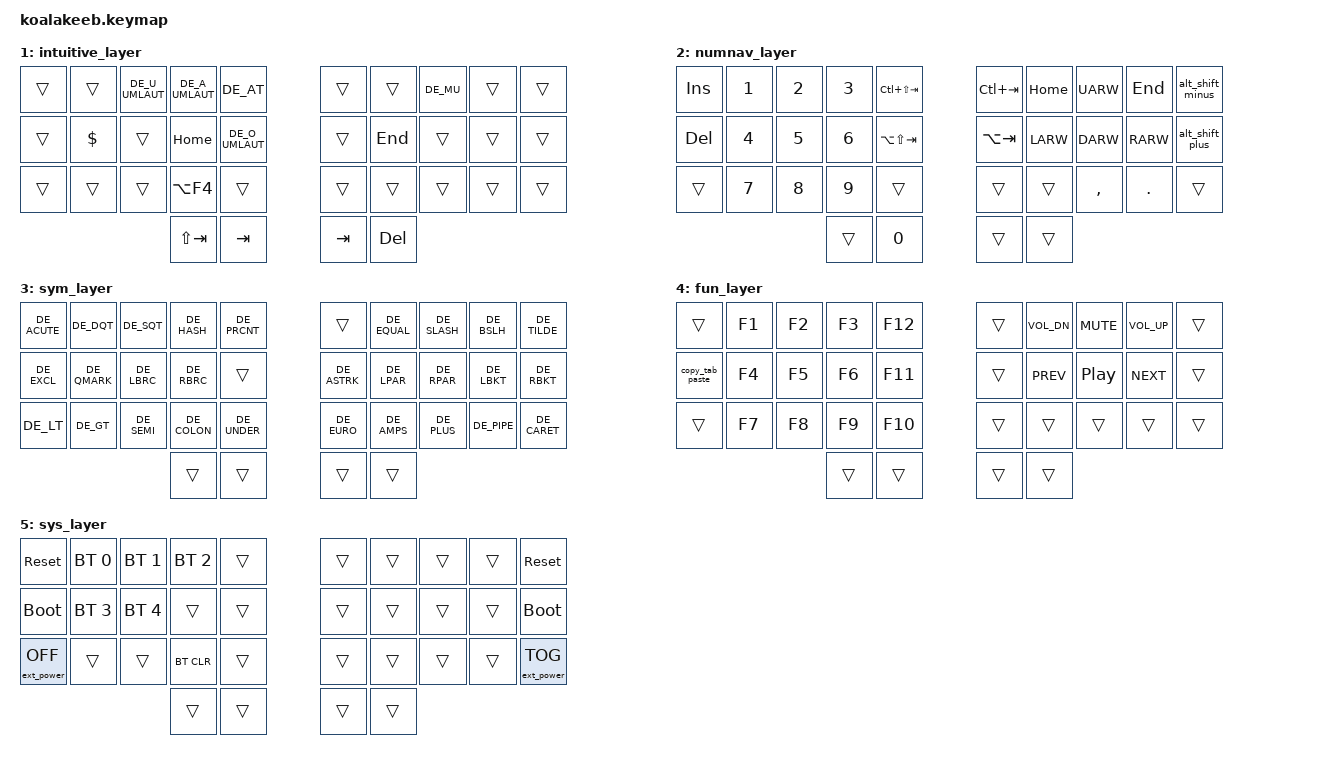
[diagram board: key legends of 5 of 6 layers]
// Copyright (c) 2022 The ZMK Contributors
// SPDX-License-Identifier: MIT

#include <behaviors.dtsi>
#include <dt-bindings/zmk/keys.h>
#include <dt-bindings/zmk/bt.h>
#include <dt-bindings/zmk/ext_power.h>
#include "keys_de.h"

// Home row mods macro
#define HRML(k1,k2,k3) &ht LALT k1  &ht LCTRL k2  &ht LGUI k3
#define HRMR(k1,k2,k3) &ht RGUI k1  &ht RCTRL k2  &ht RALT k3

/ {
    behaviors {
        ht: hold_tap {
            label = "hold_tap";
            compatible = "zmk,behavior-hold-tap";
            #binding-cells = <2>;
            flavor = "tap-preferred";
            tapping-term-ms = <220>;
            quick-tap-ms = <150>;
            global-quick-tap;
            bindings = <&kp>, <&kp>;
        };
    };

     combos {
         compatible = "zmk,combos";
         combo_esc {
            timeout-ms = <50>;
            key-positions = <0 10>;
            bindings = <&kp ESC>;
            layers = <0>;
         };
         combo_esc2 {
            timeout-ms = <50>;
            key-positions = <0 9>;
            bindings = <&kp ESC>;
            layers = <0>;
         };
         combo_capsword {
            timeout-ms = <50>;
            key-positions = <20 29>;
            bindings = <&caps_word>;
            layers = <0>;
         };
         combo_layer_sys {
             timeout-ms = <50>;
             key-positions = <30 31 32 33>;
             bindings = <&mo 5>;
         };
         combo_layer_fun {
             timeout-ms = <50>;
             key-positions = <30 31>;
             bindings = <&mo 4>;
         };
         combo_layer_fun2 {
             timeout-ms = <50>;
             key-positions = <30 33>;
             bindings = <&mo 4>;
         };
     };

     macros {
        copy_tab_paste: copy_tab_paste {
            compatible = "zmk,behavior-macro";
            #binding-cells = <0>;
            bindings
                = <&macro_press &kp LCTRL>
                , <&macro_tap &kp C &kp T &kp V>
                , <&macro_release &kp LCTRL>
                , <&macro_tap &kp ENTER>;
        };
        alt_shift_plus: alt_shift_plus {
            compatible = "zmk,behavior-macro";
            #binding-cells = <0>;
            bindings
                = <&macro_press &kp LALT>
                , <&macro_press &kp LSHFT>
                , <&macro_tap &kp DE_PLUS>
                , <&macro_release &kp LSHFT>
                , <&macro_release &kp LALT>;
        };
        alt_shift_minus: alt_shift_minus {
            compatible = "zmk,behavior-macro";
            #binding-cells = <0>;
            bindings
                = <&macro_press &kp LALT>
                , <&macro_press &kp LSHFT>
                , <&macro_tap &kp DE_MINUS>
                , <&macro_release &kp LSHFT>
                , <&macro_release &kp LALT>;
        };
     };

    keymap {
        compatible = "zmk,keymap";
        noted_layer {
            bindings = <
        //╭──────────┬──────────┬──────────┬──────────┬──────────╮   ╭──────────┬──────────┬──────────┬──────────┬──────────╮
        //│  Z       │  Y       │  U       │  A       │  Q       │   │  P       │  B       │  M       │  L       │  F       │
            &kp DE_Z   &kp DE_Y   &kp U      &kp A      &kp Q          &kp P      &kp B      &kp M      &kp L      &kp F
        //├──────────┼──────────┼──────────┼──────────┼──────────┤   ├──────────┼──────────┼──────────┼──────────┼──────────┤
        //│  C       │  S       │  I       │  E       │  O       │   │  D       │  T       │  N       │  R       │  H       │
            &lt 1 C    HRML(S,         I,         E)     &kp O          &kp D      HRMR(T,        N,         R)    &lt 1 H
        //├──────────┼──────────┼──────────┼──────────┼──────────┤   ├──────────┼──────────┼──────────┼──────────┼──────────┤
        //│  V       │  X       │  ,       │  .       │  -       │   │  W       │  G       │ J        │ ß        │   K      │
            &kp V      &kp X     &kp DE_COMMA &kp DE_DOT &kp DE_MINUS   &kp W      &kp G      &kp J     &kp DE_SZ    &kp K
        //╰──────────┴──────────┴──────────┼──────────┼──────────┤   ├──────────┼──────────┼──────────┴──────────┴──────────╯
                                            &lt 3 ENTER &kp LSHIFT    &kp SPACE   &lt 2 BSPC
        //                                 ╰──────────┴──────────╯   ╰──────────┴──────────╯
            >;
        };

        intuitive_layer {
            bindings = <
        //╭──────────┬──────────┬──────────┬──────────┬──────────╮   ╭──────────┬──────────┬──────────┬──────────┬──────────╮
        //│          │          │  Ü       │  Ä       │  @       │   │          │          │  µ       │          │          │
            &trans     &trans &kp DE_U_UMLAUT &kp DE_A_UMLAUT &kp DE_AT &trans     &trans     &kp DE_MU  &trans    &trans
        //├──────────┼──────────┼──────────┼──────────┼──────────┤   ├──────────┼──────────┼──────────┼──────────┼──────────┤
        //│          │          │          │ POS 1    │  Ö       │   │          │ END      │          │          │          │
            &trans     &kp DOLLAR &trans     &kp HOME  &kp DE_O_UMLAUT  &trans     &kp END    &trans     &trans     &trans
        //├──────────┼──────────┼──────────┼──────────┼──────────┤   ├──────────┼──────────┼──────────┼──────────┼──────────┤
        //│          │          │          │          │          │   │          │          │          │          │          │
            &trans     &trans     &trans    &kp LA(F4)  &trans          &trans     &trans     &trans     &trans     &trans
        //╰──────────┴──────────┴──────────┼──────────┼──────────┤   ├──────────┼──────────┼──────────┴──────────┴──────────╯
                                            &kp LS(TAB) &kp TAB         &kp TAB    &kp DEL
        //                                 ╰──────────┴──────────╯   ╰──────────┴──────────╯
            >;
        };

        numnav_layer {
            bindings = <
        //╭──────────┬──────────┬──────────┬──────────┬──────────╮   ╭──────────┬──────────┬──────────┬──────────┬──────────╮
        //│ INSERT   │  1       │  2       │  3       │shift-ctrl-tab│ ctrl-tab │ HOME     │ UP       │ END      │          │
            &kp INS    &kp N1     &kp N2     &kp N3   &kp LC(LS(TAB)) &kp LC(TAB) &kp HOME   &kp UARW   &kp END    &alt_shift_minus
        //├──────────┼──────────┼──────────┼──────────┼──────────┤   ├──────────┼──────────┼──────────┼──────────┼──────────┤
        //│ DELETE   │  4       │  5       │  6       │shift-alt-tab │ alt-tab  │ LEFT     │ DOWN     │ RIGHT    │          │
            &kp DEL     &kp N4   &kp N5     &kp N6    &kp LA(LS(TAB))  &kp LA(TAB) &kp LARW   &kp DARW   &kp RARW  &alt_shift_plus
        //├──────────┼──────────┼──────────┼──────────┼──────────┤   ├──────────┼──────────┼──────────┼──────────┼──────────┤
        //│          │  7       │  8       │  9       │          │   │          │          │ ,        │ .        │          │
           &trans      &kp N7     &kp N8     &kp N9     &trans         &trans     &trans     &kp COMMA  &kp DOT    &trans
        //╰──────────┴──────────┴──────────┼──────────┼──────────┤   ├──────────┼──────────┼──────────┴──────────┴──────────╯
                                             &trans     &kp N0         &trans     &trans
        //                                 ╰──────────┴──────────╯   ╰──────────┴──────────╯
            >;
        };

        sym_layer {
            bindings = <
        //╭──────────┬──────────┬──────────┬──────────┬──────────╮   ╭──────────┬──────────┬──────────┬──────────┬──────────╮
        //│  ´       │  "       │  '       │  #       │  %       │   │          │  =       │  /       │  \       │  ~       │
           &kp DE_ACUTE &kp DE_DQT &kp DE_SQT &kp DE_HASH &kp DE_PRCNT  &trans   &kp DE_EQUAL &kp DE_SLASH &kp DE_BSLH &kp DE_TILDE
        //├──────────┼──────────┼──────────┼──────────┼──────────┤   ├──────────┼──────────┼──────────┼──────────┼──────────┤
        //│  !       │  ?       │  {       │  }       │          │   │  *       │  (       │  )       │  [       │  ]       │
            &kp DE_EXCL &kp DE_QMARK &kp DE_LBRC &kp DE_RBRC &trans  &kp DE_ASTRK &kp DE_LPAR &kp DE_RPAR &kp DE_LBKT &kp DE_RBKT
        //├──────────┼──────────┼──────────┼──────────┼──────────┤   ├──────────┼──────────┼──────────┼──────────┼──────────┤
        //│  <       │  >       │          │          │          │   │  €       │  &       │  +       │  │       │  ^       │
            &kp DE_LT  &kp DE_GT &kp DE_SEMI &kp DE_COLON &kp DE_UNDER &kp DE_EURO &kp DE_AMPS &kp DE_PLUS &kp DE_PIPE &kp DE_CARET
        //╰──────────┴──────────┴──────────┼──────────┼──────────┤   ├──────────┼──────────┼──────────┴──────────┴──────────╯
                                             &trans     &trans         &trans     &trans
        //                                 ╰──────────┴──────────╯   ╰──────────┴──────────╯
            >;
        };

        fun_layer {
            bindings = <
        //╭──────────┬──────────┬──────────┬──────────┬──────────╮   ╭──────────┬──────────┬──────────┬──────────┬──────────╮
        //│          │          │          │          │          │   │          │ vol down │ mute     │  vol up  │          │
            &trans     &kp F1     &kp F2     &kp F3    &kp F12        &trans    &kp C_VOL_DN &kp C_MUTE &kp C_VOL_UP &trans
        //├──────────┼──────────┼──────────┼──────────┼──────────┤   ├──────────┼──────────┼──────────┼──────────┼──────────┤
        //|          │          │          │          │          │   │          │ previous │playpause │ next     │          |
          &copy_tab_paste &kp F4  &kp F5     &kp F6    &kp F11         &trans    &kp C_PREV  &kp C_PP   &kp C_NEXT  &trans
        //├──────────┼──────────┼──────────┼──────────┼──────────┤   ├──────────┼──────────┼──────────┼──────────┼──────────┤
        //│          │          │          │          │          │   │          │          │          │          │          │
            &trans     &kp F7     &kp F8    &kp F9     &kp F10         &trans     &trans     &trans     &trans     &trans
        //╰──────────┴──────────┴──────────┼──────────┼──────────┤   ├──────────┼──────────┼──────────┴──────────┴──────────╯
                                             &trans     &trans         &trans     &trans
        //                                 ╰──────────┴──────────╯   ╰──────────┴──────────╯
            >;
        };

        sys_layer {
            bindings = <
        //╭──────────┬──────────┬──────────┬──────────┬──────────╮   ╭──────────┬──────────┬──────────┬──────────┬──────────╮
        //│ RESET    │ PROFILE 0│PROFILE 1 │PROFILE 2 │          │   │          │          │          │          │  RESET   │
         &sys_reset &bt BT_SEL 0 &bt BT_SEL 1 &bt BT_SEL 2 &trans      &trans     &trans     &trans     &trans    &sys_reset
        //├──────────┼──────────┼──────────┼──────────┼──────────┤   ├──────────┼──────────┼──────────┼──────────┼──────────┤
        //│BOOTLOADER│ PROFILE 3│PROFILE 4 │          │          │   │          │          │          │          │BOOTLOADER│
          &bootloader &bt BT_SEL 3 &bt BT_SEL 4 &trans &trans          &trans     &trans     &trans     &trans    &bootloader
        //├──────────┼──────────┼──────────┼──────────┼──────────┤   ├──────────┼──────────┼──────────┼──────────┼──────────┤
        //│          │          │          │ CLEAR BT │          │   │          │          │          │          │          │
     &ext_power EP_OFF &trans     &trans    &bt BT_CLR &trans          &trans     &trans     &trans     &trans  &ext_power EP_TOG
        //╰──────────┴──────────┴──────────┼──────────┼──────────┤   ├──────────┼──────────┼──────────┴──────────┴──────────╯
                                             &trans     &trans         &trans     &trans
        //                                 ╰──────────┴──────────╯   ╰──────────┴──────────╯
            >;
        };
    };
};
